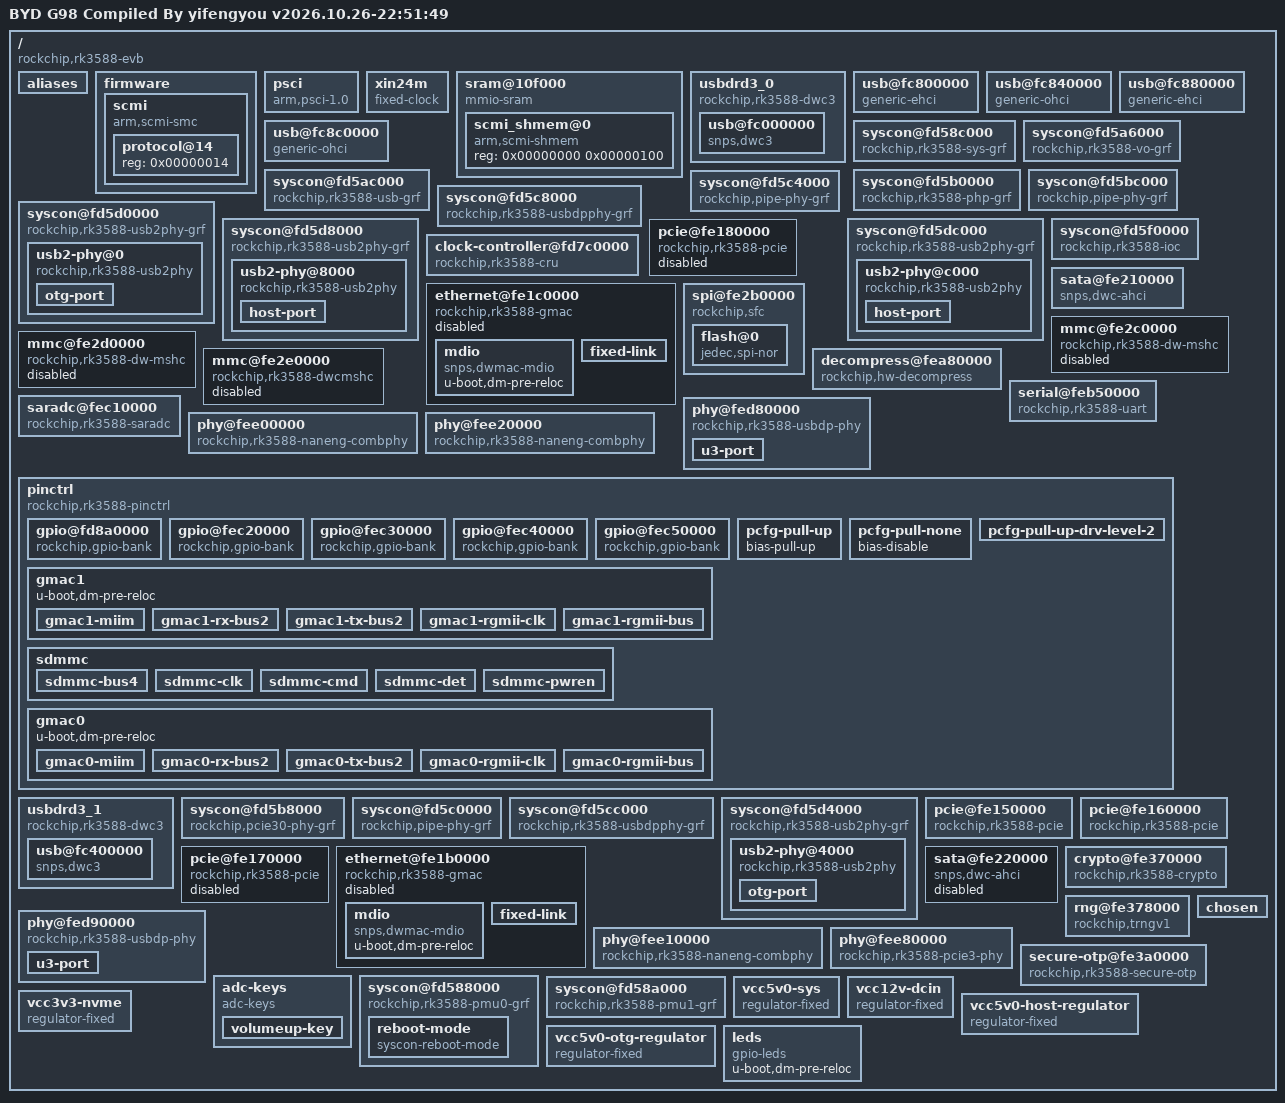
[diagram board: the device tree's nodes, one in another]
/dts-v1/;
// magic:		0xd00dfeed
// totalsize:		0x6047 (24647)
// off_dt_struct:	0x38
// off_dt_strings:	0x5850
// off_mem_rsvmap:	0x28
// version:		17
// last_comp_version:	16
// boot_cpuid_phys:	0x0
// size_dt_strings:	0x7f7
// size_dt_struct:	0x5818

/ {
    compatible = "rockchip,rk3588-evb", "rockchip,rk3588";
    #address-cells = <0x00000002>;
    #size-cells = <0x00000002>;
    model = "BYD G98 Compiled By yifengyou v2026.10.26-22:51:49";
    aliases {
        ethernet1 = "/pcie@fe170000";
        serial2 = "/serial@feb50000";
        spi0 = "/spi@fe2b0000";
        spi5 = "/spi@fe2b0000";
        gpio0 = "/pinctrl/gpio@fd8a0000";
        gpio1 = "/pinctrl/gpio@fec20000";
        gpio2 = "/pinctrl/gpio@fec30000";
        gpio3 = "/pinctrl/gpio@fec40000";
        gpio4 = "/pinctrl/gpio@fec50000";
        ethernet0 = "/pcie@fe180000";
        mmc0 = "/mmc@fe2e0000";
        mmc1 = "/mmc@fe2c0000";
    };
    firmware {
        u-boot,dm-spl;
        scmi {
            compatible = "arm,scmi-smc";
            shmem = <0x10000009>;
            arm,smc-id = <0x82000010>;
            #address-cells = <0x00000001>;
            #size-cells = <0x00000000>;
            u-boot,dm-spl;
            protocol@14 {
                reg = <0x00000014>;
                #clock-cells = <0x00000001>;
                u-boot,dm-spl;
                phandle = <0x1000000a>;
            };
        };
    };
    psci {
        compatible = "arm,psci-1.0";
        method = "smc";
        u-boot,dm-pre-reloc;
        status = "okay";
    };
    xin24m {
        compatible = "fixed-clock";
        #clock-cells = <0x00000000>;
        clock-frequency = <0x016e3600>;
        clock-output-names = "xin24m";
        u-boot,dm-pre-reloc;
        status = "okay";
    };
    sram@10f000 {
        compatible = "mmio-sram";
        reg = <0x00000000 0x0010f000 0x00000000 0x00000100>;
        #address-cells = <0x00000001>;
        #size-cells = <0x00000001>;
        ranges = <0x00000000 0x00000000 0x0010f000 0x00000100>;
        u-boot,dm-spl;
        scmi_shmem@0 {
            compatible = "arm,scmi-shmem";
            reg = <0x00000000 0x00000100>;
            u-boot,dm-spl;
            phandle = <0x10000009>;
        };
    };
    usbdrd3_0 {
        compatible = "rockchip,rk3588-dwc3", "rockchip,rk3399-dwc3";
        clocks = <0x1000000b 0x000001a3 0x1000000b 0x000001a2 0x1000000b 0x000001a1>;
        #address-cells = <0x00000002>;
        #size-cells = <0x00000002>;
        ranges;
        status = "okay";
        dr_mode = "otg";
        u-boot,dm-pre-reloc;
        usb@fc000000 {
            compatible = "snps,dwc3";
            reg = <0x00000000 0xfc000000 0x00000000 0x00400000>;
            interrupts = <0x00000000 0x000000dc 0x00000004>;
            power-domains = <0x1000000c 0x0000001f>;
            resets = <0x1000000b 0x000002a4>;
            reset-names = "usb3-otg";
            dr_mode = "otg";
            phys = <0x1000000d 0x1000000e>;
            phy-names = "usb2-phy", "usb3-phy";
            phy_type = "utmi_wide";
            snps,dis_enblslpm_quirk;
            snps,dis-u1-entry-quirk;
            snps,dis-u2-entry-quirk;
            snps,dis-u2-freeclk-exists-quirk;
            snps,dis-del-phy-power-chg-quirk;
            snps,dis-tx-ipgap-linecheck-quirk;
            status = "okay";
            maximum-speed = "super-speed";
            u-boot,dm-pre-reloc;
        };
    };
    usb@fc800000 {
        compatible = "generic-ehci";
        reg = <0x00000000 0xfc800000 0x00000000 0x00040000>;
        interrupts = <0x00000000 0x000000d7 0x00000004>;
        clocks = <0x1000000b 0x0000019d 0x1000000b 0x0000019e>;
        phys = <0x1000000f>;
        phy-names = "usb2-phy";
        power-domains = <0x1000000c 0x0000001f>;
        status = "okay";
        u-boot,dm-pre-reloc;
    };
    usb@fc840000 {
        compatible = "generic-ohci";
        reg = <0x00000000 0xfc840000 0x00000000 0x00040000>;
        interrupts = <0x00000000 0x000000d8 0x00000004>;
        clocks = <0x1000000b 0x0000019d 0x1000000b 0x0000019e>;
        phys = <0x1000000f>;
        phy-names = "usb2-phy";
        power-domains = <0x1000000c 0x0000001f>;
        status = "okay";
        u-boot,dm-pre-reloc;
    };
    usb@fc880000 {
        compatible = "generic-ehci";
        reg = <0x00000000 0xfc880000 0x00000000 0x00040000>;
        interrupts = <0x00000000 0x000000da 0x00000004>;
        clocks = <0x1000000b 0x0000019f 0x1000000b 0x000001a0>;
        phys = <0x10000010>;
        phy-names = "usb2-phy";
        power-domains = <0x1000000c 0x0000001f>;
        status = "okay";
        u-boot,dm-pre-reloc;
    };
    usb@fc8c0000 {
        compatible = "generic-ohci";
        reg = <0x00000000 0xfc8c0000 0x00000000 0x00040000>;
        interrupts = <0x00000000 0x000000db 0x00000004>;
        clocks = <0x1000000b 0x0000019f 0x1000000b 0x000001a0>;
        phys = <0x10000010>;
        phy-names = "usb2-phy";
        power-domains = <0x1000000c 0x0000001f>;
        status = "okay";
        u-boot,dm-pre-reloc;
    };
    syscon@fd58c000 {
        compatible = "rockchip,rk3588-sys-grf", "syscon";
        reg = <0x00000000 0xfd58c000 0x00000000 0x00001000>;
        u-boot,dm-spl;
        status = "okay";
        u-boot,dm-pre-reloc;
        phandle = <0x10000027>;
    };
    syscon@fd5a6000 {
        compatible = "rockchip,rk3588-vo-grf", "syscon";
        reg = <0x00000000 0xfd5a6000 0x00000000 0x00002000>;
        status = "okay";
        u-boot,dm-pre-reloc;
        phandle = <0x1000009b>;
    };
    syscon@fd5ac000 {
        compatible = "rockchip,rk3588-usb-grf", "syscon";
        reg = <0x00000000 0xfd5ac000 0x00000000 0x00004000>;
        u-boot,dm-pre-reloc;
        status = "okay";
        phandle = <0x10000099>;
    };
    syscon@fd5b0000 {
        compatible = "rockchip,rk3588-php-grf", "syscon";
        reg = <0x00000000 0xfd5b0000 0x00000000 0x00001000>;
        u-boot,dm-pre-reloc;
        status = "okay";
        phandle = <0x10000013>;
    };
    syscon@fd5bc000 {
        compatible = "rockchip,pipe-phy-grf", "syscon";
        reg = <0x00000000 0xfd5bc000 0x00000000 0x00000100>;
        u-boot,dm-pre-reloc;
        status = "okay";
        phandle = <0x1000009c>;
    };
    syscon@fd5c4000 {
        compatible = "rockchip,pipe-phy-grf", "syscon";
        reg = <0x00000000 0xfd5c4000 0x00000000 0x00000100>;
        u-boot,dm-pre-reloc;
        status = "okay";
        phandle = <0x1000009e>;
    };
    syscon@fd5c8000 {
        compatible = "rockchip,rk3588-usbdpphy-grf", "syscon";
        reg = <0x00000000 0xfd5c8000 0x00000000 0x00004000>;
        u-boot,dm-pre-reloc;
        status = "okay";
        phandle = <0x1000009a>;
    };
    syscon@fd5d0000 {
        compatible = "rockchip,rk3588-usb2phy-grf", "syscon", "simple-mfd";
        reg = <0x00000000 0xfd5d0000 0x00000000 0x00004000>;
        #address-cells = <0x00000001>;
        #size-cells = <0x00000001>;
        u-boot,dm-pre-reloc;
        status = "okay";
        phandle = <0x10000098>;
        usb2-phy@0 {
            compatible = "rockchip,rk3588-usb2phy";
            reg = <0x00000000 0x00000010>;
            interrupts = <0x00000000 0x00000189 0x00000004>;
            resets = <0x1000000b 0x000c0047 0x1000000b 0x00000488>;
            reset-names = "phy", "apb";
            clocks = <0x1000000b 0x000002b5>;
            #clock-cells = <0x00000000>;
            status = "okay";
            u-boot,dm-pre-reloc;
            otg-port {
                #phy-cells = <0x00000000>;
                status = "okay";
                u-boot,dm-pre-reloc;
                phy-supply = <0x10000011>;
                phandle = <0x1000000d>;
            };
        };
    };
    syscon@fd5d8000 {
        compatible = "rockchip,rk3588-usb2phy-grf", "syscon", "simple-mfd";
        reg = <0x00000000 0xfd5d8000 0x00000000 0x00004000>;
        #address-cells = <0x00000001>;
        #size-cells = <0x00000001>;
        status = "okay";
        u-boot,dm-pre-reloc;
        usb2-phy@8000 {
            compatible = "rockchip,rk3588-usb2phy";
            reg = <0x00008000 0x00000010>;
            interrupts = <0x00000000 0x00000187 0x00000004>;
            resets = <0x1000000b 0x000c0049 0x1000000b 0x0000048a>;
            reset-names = "phy", "apb";
            clocks = <0x1000000b 0x000002b5>;
            #clock-cells = <0x00000000>;
            status = "okay";
            u-boot,dm-pre-reloc;
            host-port {
                #phy-cells = <0x00000000>;
                status = "okay";
                phy-supply = <0x10000012>;
                u-boot,dm-pre-reloc;
                phandle = <0x1000000f>;
            };
        };
    };
    syscon@fd5dc000 {
        compatible = "rockchip,rk3588-usb2phy-grf", "syscon", "simple-mfd";
        reg = <0x00000000 0xfd5dc000 0x00000000 0x00004000>;
        #address-cells = <0x00000001>;
        #size-cells = <0x00000001>;
        status = "okay";
        u-boot,dm-pre-reloc;
        usb2-phy@c000 {
            compatible = "rockchip,rk3588-usb2phy";
            reg = <0x0000c000 0x00000010>;
            interrupts = <0x00000000 0x00000188 0x00000004>;
            resets = <0x1000000b 0x000c004a 0x1000000b 0x0000048b>;
            reset-names = "phy", "apb";
            clocks = <0x1000000b 0x000002b5>;
            #clock-cells = <0x00000000>;
            status = "okay";
            u-boot,dm-pre-reloc;
            host-port {
                #phy-cells = <0x00000000>;
                status = "okay";
                phy-supply = <0x10000012>;
                u-boot,dm-pre-reloc;
                phandle = <0x10000010>;
            };
        };
    };
    syscon@fd5f0000 {
        compatible = "rockchip,rk3588-ioc", "syscon";
        reg = <0x00000000 0xfd5f0000 0x00000000 0x00010000>;
        u-boot,dm-spl;
        phandle = <0x1000009f>;
    };
    clock-controller@fd7c0000 {
        compatible = "rockchip,rk3588-cru";
        rockchip,grf = <0x10000013>;
        reg = <0x00000000 0xfd7c0000 0x00000000 0x0005c000>;
        #clock-cells = <0x00000001>;
        #reset-cells = <0x00000001>;
        u-boot,dm-spl;
        status = "okay";
        phandle = <0x1000000b>;
    };
    pcie@fe180000 {
        compatible = "rockchip,rk3588-pcie", "snps,dw-pcie";
        #address-cells = <0x00000003>;
        #size-cells = <0x00000002>;
        bus-range = <0x00000030 0x0000003f>;
        clocks = <0x1000000b 0x00000151 0x1000000b 0x00000156 0x1000000b 0x0000014c 0x1000000b 0x0000015c 0x1000000b 0x00000161>;
        device_type = "pci";
        interrupts = <0x00000000 0x000000f8 0x00000004 0x00000000 0x000000f7 0x00000004 0x00000000 0x000000f6 0x00000004 0x00000000 0x000000f5 0x00000004 0x00000000 0x000000f4 0x00000004>;
        interrupt-names = "sys", "pmc", "msg", "legacy", "err";
        #interrupt-cells = <0x00000001>;
        interrupt-map-mask = <0x00000000 0x00000000 0x00000000 0x00000007>;
        interrupt-map = <0x00000000 0x00000000 0x00000000 0x00000001 0x1000001f 0x00000000 0x00000000 0x00000000 0x00000000 0x00000002 0x1000001f 0x00000001 0x00000000 0x00000000 0x00000000 0x00000003 0x1000001f 0x00000002 0x00000000 0x00000000 0x00000000 0x00000004 0x1000001f 0x00000003>;
        linux,pci-domain = <0x00000003>;
        num-ib-windows = <0x00000008>;
        num-ob-windows = <0x00000008>;
        max-link-speed = <0x00000002>;
        msi-map = <0x00003000 0x10000020 0x00003000 0x00001000>;
        num-lanes = <0x00000001>;
        phys = <0x10000021 0x00000002>;
        phy-names = "pcie-phy";
        power-domains = <0x1000000c 0x00000020>;
        ranges = <0x00000800 0x00000000 0xf3000000 0x00000000 0xf3000000 0x00000000 0x00100000 0x81000000 0x00000000 0xf3100000 0x00000000 0xf3100000 0x00000000 0x00100000 0x82000000 0x00000000 0xf3200000 0x00000000 0xf3200000 0x00000000 0x00e00000 0xc3000000 0x00000009 0xc0000000 0x00000009 0xc0000000 0x00000000 0x40000000>;
        reg = <0x0000000a 0x40c00000 0x00000000 0x00400000 0x00000000 0xfe180000 0x00000000 0x00010000>;
        reg-names = "pcie-dbi", "pcie-apb";
        resets = <0x1000000b 0x00000210>;
        reset-names = "pipe";
        status = "disabled";
        supports-clkreq;
        reset-gpios = <0x10000023 0x00000002 0x00000000>;
        vpcie3v3-supply = <0x10000024>;
        reset-delay-us = <0x000186a0>;
        u-boot,dm-pre-reloc;
    };
    ethernet@fe1c0000 {
        compatible = "rockchip,rk3588-gmac", "snps,dwmac-4.20a";
        reg = <0x00000000 0xfe1c0000 0x00000000 0x00010000>;
        interrupts = <0x00000000 0x000000ea 0x00000004 0x00000000 0x000000e9 0x00000004>;
        interrupt-names = "macirq", "eth_wake_irq";
        rockchip,grf = <0x10000027>;
        rockchip,php_grf = <0x10000013>;
        clocks = <0x1000000b 0x000002b4 0x1000000b 0x0000016d 0x1000000b 0x00000168 0x1000000b 0x00000143>;
        resets = <0x1000000b 0x0000020b>;
        reset-names = "stmmaceth";
        snps,mixed-burst;
        snps,tso;
        snps,axi-config = <0x10000028>;
        snps,mtl-rx-config = <0x10000029>;
        snps,mtl-tx-config = <0x1000002a>;
        status = "disabled";
        clock_in_out = "output";
        phy-mode = "rgmii-rxid";
        tx_delay = <0x00000042>;
        snps,reset-active-low;
        snps,reset-delays-us = <0x00000000 0x00004e20 0x000186a0>;
        snps,reset-gpio = <0x10000023 0x0000000b 0x00000001>;
        u-boot,dm-pre-reloc;
        phandle = <0x10000030>;
        mdio {
            compatible = "snps,dwmac-mdio";
            #address-cells = <0x00000001>;
            #size-cells = <0x00000000>;
            u-boot,dm-pre-reloc;
            status = "okay";
        };
        fixed-link {
            full-duplex;
            pause;
            speed = <0x000003e8>;
            u-boot,dm-pre-reloc;
            status = "okay";
        };
    };
    sata@fe210000 {
        compatible = "snps,dwc-ahci";
        reg = <0x00000000 0xfe210000 0x00000000 0x00001000>;
        clocks = <0x1000000b 0x00000171 0x1000000b 0x0000016e 0x1000000b 0x00000174 0x1000000b 0x00000163>;
        interrupts = <0x00000000 0x00000111 0x00000004>;
        interrupt-names = "hostc";
        phys = <0x10000026 0x00000001>;
        phy-names = "sata-phy";
        ports-implemented = <0x00000001>;
        power-domains = <0x1000000c 0x00000020>;
        status = "okay";
        u-boot,dm-pre-reloc;
    };
    spi@fe2b0000 {
        compatible = "rockchip,sfc";
        reg = <0x00000000 0xfe2b0000 0x00000000 0x00004000>;
        interrupts = <0x00000000 0x000000ce 0x00000004>;
        clocks = <0x1000000b 0x0000013d 0x1000000b 0x0000013e>;
        #address-cells = <0x00000001>;
        #size-cells = <0x00000000>;
        status = "okay";
        u-boot,dm-spl;
        u-boot,dm-pre-reloc;
        flash@0 {
            u-boot,dm-spl;
            compatible = "jedec,spi-nor";
            reg = <0x00000000>;
            spi-tx-bus-width = <0x00000001>;
            spi-rx-bus-width = <0x00000004>;
            spi-max-frequency = <0x05f5e100>;
            status = "okay";
            label = "sfc_nor";
            spi-4byte-addressing;
            broken-flash-reset;
            u-boot,dm-pre-reloc;
        };
    };
    mmc@fe2c0000 {
        compatible = "rockchip,rk3588-dw-mshc", "rockchip,rk3288-dw-mshc";
        reg = <0x00000000 0xfe2c0000 0x00000000 0x00004000>;
        interrupts = <0x00000000 0x000000cb 0x00000004>;
        clocks = <0x1000000a 0x00000009 0x1000000a 0x00000017 0x1000000b 0x000002c2 0x1000000b 0x000002c3>;
        fifo-depth = <0x00000100>;
        max-frequency = <0x0bebc200>;
        status = "disabled";
        bus-width = <0x00000004>;
        u-boot,dm-spl;
        cd-gpios = <0x10000035 0x00000004 0x00000000>;
        u-boot,dm-pre-reloc;
    };
    mmc@fe2d0000 {
        compatible = "rockchip,rk3588-dw-mshc", "rockchip,rk3288-dw-mshc";
        reg = <0x00000000 0xfe2d0000 0x00000000 0x00004000>;
        interrupts = <0x00000000 0x000000cc 0x00000004>;
        clocks = <0x1000000b 0x00000199 0x1000000b 0x0000019a 0x1000000b 0x000002c0 0x1000000b 0x000002c1>;
        fifo-depth = <0x00000100>;
        max-frequency = <0x0bebc200>;
        status = "disabled";
        u-boot,dm-pre-reloc;
    };
    mmc@fe2e0000 {
        compatible = "rockchip,rk3588-dwcmshc", "rockchip,dwcmshc-sdhci";
        reg = <0x00000000 0xfe2e0000 0x00000000 0x00010000>;
        interrupts = <0x00000000 0x000000cd 0x00000004>;
        clocks = <0x1000000b 0x0000013a 0x1000000b 0x00000138 0x1000000b 0x00000139 0x1000000b 0x0000013b 0x1000000b 0x0000013c>;
        max-frequency = <0x0bebc200>;
        status = "disabled";
        bus-width = <0x00000008>;
        u-boot,dm-spl;
        mmc-hs400-1_8v;
        mmc-hs400-enhanced-strobe;
        non-removable;
    };
    decompress@fea80000 {
        compatible = "rockchip,hw-decompress";
        reg = <0x00000000 0xfea80000 0x00000000 0x00001000>;
        interrupts = <0x00000000 0x00000055 0x00000004>;
        clocks = <0x1000000b 0x00000075 0x1000000b 0x00000077 0x1000000b 0x00000076>;
        resets = <0x1000000b 0x00000118>;
        reset-names = "dresetn";
        status = "okay";
        u-boot,dm-spl;
    };
    serial@feb50000 {
        compatible = "rockchip,rk3588-uart", "snps,dw-apb-uart";
        reg = <0x00000000 0xfeb50000 0x00000000 0x00000100>;
        interrupts = <0x00000000 0x0000014d 0x00000004>;
        clocks = <0x1000000b 0x000000bb 0x1000000b 0x000000ac>;
        reg-shift = <0x00000002>;
        reg-io-width = <0x00000004>;
        dmas = <0x10000015 0x0000000a 0x10000015 0x0000000b>;
        status = "okay";
        u-boot,dm-spl;
    };
    saradc@fec10000 {
        compatible = "rockchip,rk3588-saradc";
        reg = <0x00000000 0xfec10000 0x00000000 0x00010000>;
        interrupts = <0x00000000 0x0000018e 0x00000004>;
        #io-channel-cells = <0x00000001>;
        clocks = <0x1000000b 0x0000009d 0x1000000b 0x0000009c>;
        resets = <0x1000000b 0x000000be>;
        reset-names = "saradc-apb";
        status = "okay";
        u-boot,dm-pre-reloc;
        phandle = <0x100000c2>;
    };
    phy@fed80000 {
        compatible = "rockchip,rk3588-usbdp-phy";
        reg = <0x00000000 0xfed80000 0x00000000 0x00010000>;
        rockchip,u2phy-grf = <0x10000098>;
        rockchip,usb-grf = <0x10000099>;
        rockchip,usbdpphy-grf = <0x1000009a>;
        rockchip,vo-grf = <0x1000009b>;
        clocks = <0x1000000b 0x000002b6 0x1000000b 0x0000027f 0x1000000b 0x00000269>;
        resets = <0x1000000b 0x00000028 0x1000000b 0x00000029 0x1000000b 0x0000002a 0x1000000b 0x0000002b 0x1000000b 0x00000482>;
        reset-names = "init", "cmn", "lane", "pcs_apb", "pma_apb";
        status = "okay";
        u-boot,dm-pre-reloc;
        u3-port {
            #phy-cells = <0x00000000>;
            status = "okay";
            u-boot,dm-pre-reloc;
            maximum-speed = "high-speed";
            phandle = <0x1000000e>;
        };
    };
    phy@fee00000 {
        compatible = "rockchip,rk3588-naneng-combphy";
        reg = <0x00000000 0xfee00000 0x00000000 0x00000100>;
        #phy-cells = <0x00000001>;
        clocks = <0x1000000b 0x000002bd 0x1000000b 0x00000185>;
        resets = <0x1000000b 0x00020005 0x1000000b 0x000004d6>;
        reset-names = "combphy-apb", "combphy";
        rockchip,pipe-grf = <0x10000013>;
        rockchip,pipe-phy-grf = <0x1000009c>;
        status = "okay";
        phy-type = <0x00000001>;
        u-boot,dm-pre-reloc;
        phandle = <0x10000026>;
    };
    phy@fee20000 {
        compatible = "rockchip,rk3588-naneng-combphy";
        reg = <0x00000000 0xfee20000 0x00000000 0x00000100>;
        #phy-cells = <0x00000001>;
        clocks = <0x1000000b 0x000002bf 0x1000000b 0x00000187>;
        resets = <0x1000000b 0x00020007 0x1000000b 0x000004d8>;
        reset-names = "combphy-apb", "combphy";
        rockchip,pipe-grf = <0x10000013>;
        rockchip,pipe-phy-grf = <0x1000009e>;
        rockchip,pcie1ln-sel-bits = <0x00000100 0x00000001 0x00000001 0x00000000>;
        status = "okay";
        u-boot,dm-pre-reloc;
        phandle = <0x10000021>;
    };
    pinctrl {
        compatible = "rockchip,rk3588-pinctrl";
        rockchip,grf = <0x1000009f>;
        #address-cells = <0x00000002>;
        #size-cells = <0x00000002>;
        ranges;
        u-boot,dm-spl;
        u-boot,dm-pre-reloc;
        phandle = <0x100000a0>;
        gpio@fd8a0000 {
            compatible = "rockchip,gpio-bank";
            reg = <0x00000000 0xfd8a0000 0x00000000 0x00000100>;
            interrupts = <0x00000000 0x00000115 0x00000004>;
            clocks = <0x1000000b 0x00000284 0x1000000b 0x00000285>;
            gpio-controller;
            #gpio-cells = <0x00000002>;
            gpio-ranges = <0x100000a0 0x00000000 0x00000000 0x00000020>;
            interrupt-controller;
            #interrupt-cells = <0x00000002>;
            u-boot,dm-spl;
            status = "okay";
            u-boot,dm-pre-reloc;
            phandle = <0x10000035>;
        };
        gpio@fec20000 {
            compatible = "rockchip,gpio-bank";
            reg = <0x00000000 0xfec20000 0x00000000 0x00000100>;
            interrupts = <0x00000000 0x00000116 0x00000004>;
            clocks = <0x1000000b 0x0000007d 0x1000000b 0x0000007e>;
            gpio-controller;
            #gpio-cells = <0x00000002>;
            gpio-ranges = <0x100000a0 0x00000000 0x00000020 0x00000020>;
            interrupt-controller;
            #interrupt-cells = <0x00000002>;
            u-boot,dm-pre-reloc;
            status = "okay";
            phandle = <0x100000b3>;
        };
        gpio@fec30000 {
            compatible = "rockchip,gpio-bank";
            reg = <0x00000000 0xfec30000 0x00000000 0x00000100>;
            interrupts = <0x00000000 0x00000117 0x00000004>;
            clocks = <0x1000000b 0x0000007f 0x1000000b 0x00000080>;
            gpio-controller;
            #gpio-cells = <0x00000002>;
            gpio-ranges = <0x100000a0 0x00000000 0x00000040 0x00000020>;
            interrupt-controller;
            #interrupt-cells = <0x00000002>;
            u-boot,dm-pre-reloc;
            status = "okay";
        };
        gpio@fec40000 {
            compatible = "rockchip,gpio-bank";
            reg = <0x00000000 0xfec40000 0x00000000 0x00000100>;
            interrupts = <0x00000000 0x00000118 0x00000004>;
            clocks = <0x1000000b 0x00000081 0x1000000b 0x00000082>;
            gpio-controller;
            #gpio-cells = <0x00000002>;
            gpio-ranges = <0x100000a0 0x00000000 0x00000060 0x00000020>;
            interrupt-controller;
            #interrupt-cells = <0x00000002>;
            u-boot,dm-pre-reloc;
            status = "okay";
            phandle = <0x100000af>;
        };
        gpio@fec50000 {
            compatible = "rockchip,gpio-bank";
            reg = <0x00000000 0xfec50000 0x00000000 0x00000100>;
            interrupts = <0x00000000 0x00000119 0x00000004>;
            clocks = <0x1000000b 0x00000083 0x1000000b 0x00000084>;
            gpio-controller;
            #gpio-cells = <0x00000002>;
            gpio-ranges = <0x100000a0 0x00000000 0x00000080 0x00000020>;
            interrupt-controller;
            #interrupt-cells = <0x00000002>;
            u-boot,dm-pre-reloc;
            status = "okay";
            phandle = <0x10000023>;
        };
        pcfg-pull-up {
            bias-pull-up;
            u-boot,dm-spl;
            phandle = <0x100000a3>;
        };
        pcfg-pull-none {
            bias-disable;
            u-boot,dm-spl;
            phandle = <0x100000a1>;
        };
        pcfg-pull-up-drv-level-2 {
            bias-pull-up;
            drive-strength = <0x00000002>;
            u-boot,dm-spl;
            phandle = <0x100000a2>;
        };
        gmac1 {
            u-boot,dm-pre-reloc;
            gmac1-miim {
                rockchip,pins = <0x00000003 0x00000012 0x00000001 0x100000a1 0x00000003 0x00000013 0x00000001 0x100000a1>;
                u-boot,dm-pre-reloc;
                phandle = <0x1000002b>;
            };
            gmac1-rx-bus2 {
                rockchip,pins = <0x00000003 0x00000007 0x00000001 0x100000a1 0x00000003 0x00000008 0x00000001 0x100000a1 0x00000003 0x00000009 0x00000001 0x100000a1>;
                u-boot,dm-pre-reloc;
                phandle = <0x1000002d>;
            };
            gmac1-tx-bus2 {
                rockchip,pins = <0x00000003 0x0000000b 0x00000001 0x100000a1 0x00000003 0x0000000c 0x00000001 0x100000a1 0x00000003 0x0000000d 0x00000001 0x100000a1>;
                u-boot,dm-pre-reloc;
                phandle = <0x1000002c>;
            };
            gmac1-rgmii-clk {
                rockchip,pins = <0x00000003 0x00000005 0x00000001 0x100000a1 0x00000003 0x00000004 0x00000001 0x100000a1>;
                u-boot,dm-pre-reloc;
                phandle = <0x1000002e>;
            };
            gmac1-rgmii-bus {
                rockchip,pins = <0x00000003 0x00000002 0x00000001 0x100000a1 0x00000003 0x00000003 0x00000001 0x100000a1 0x00000003 0x00000000 0x00000001 0x100000a1 0x00000003 0x00000001 0x00000001 0x100000a1>;
                u-boot,dm-pre-reloc;
                phandle = <0x1000002f>;
            };
        };
        sdmmc {
            u-boot,dm-spl;
            sdmmc-bus4 {
                rockchip,pins = <0x00000004 0x00000018 0x00000001 0x100000a2 0x00000004 0x00000019 0x00000001 0x100000a2 0x00000004 0x0000001a 0x00000001 0x100000a2 0x00000004 0x0000001b 0x00000001 0x100000a2>;
                u-boot,dm-spl;
                phandle = <0x10000034>;
            };
            sdmmc-clk {
                rockchip,pins = <0x00000004 0x0000001d 0x00000001 0x100000a2>;
                u-boot,dm-spl;
                phandle = <0x10000031>;
            };
            sdmmc-cmd {
                rockchip,pins = <0x00000004 0x0000001c 0x00000001 0x100000a2>;
                u-boot,dm-spl;
                phandle = <0x10000032>;
            };
            sdmmc-det {
                rockchip,pins = <0x00000000 0x00000004 0x00000001 0x100000a3>;
                u-boot,dm-spl;
                phandle = <0x10000033>;
            };
            sdmmc-pwren {
                rockchip,pins = <0x00000000 0x00000005 0x00000002 0x100000a1>;
                u-boot,dm-spl;
            };
        };
        gmac0 {
            u-boot,dm-pre-reloc;
            gmac0-miim {
                rockchip,pins = <0x00000004 0x00000014 0x00000001 0x100000a1 0x00000004 0x00000015 0x00000001 0x100000a1>;
                u-boot,dm-pre-reloc;
                phandle = <0x100000b7>;
            };
            gmac0-rx-bus2 {
                rockchip,pins = <0x00000002 0x00000011 0x00000001 0x100000a1 0x00000002 0x00000012 0x00000001 0x100000a1 0x00000004 0x00000012 0x00000001 0x100000a1>;
                u-boot,dm-pre-reloc;
                phandle = <0x100000b9>;
            };
            gmac0-tx-bus2 {
                rockchip,pins = <0x00000002 0x0000000e 0x00000001 0x100000a1 0x00000002 0x0000000f 0x00000001 0x100000a1 0x00000002 0x00000010 0x00000001 0x100000a1>;
                u-boot,dm-pre-reloc;
                phandle = <0x100000b8>;
            };
            gmac0-rgmii-clk {
                rockchip,pins = <0x00000002 0x00000008 0x00000001 0x100000a1 0x00000002 0x0000000b 0x00000001 0x100000a1>;
                u-boot,dm-pre-reloc;
                phandle = <0x100000ba>;
            };
            gmac0-rgmii-bus {
                rockchip,pins = <0x00000002 0x00000006 0x00000001 0x100000a1 0x00000002 0x00000007 0x00000001 0x100000a1 0x00000002 0x00000009 0x00000001 0x100000a1 0x00000002 0x0000000a 0x00000001 0x100000a1>;
                u-boot,dm-pre-reloc;
                phandle = <0x100000bb>;
            };
        };
    };
    usbdrd3_1 {
        compatible = "rockchip,rk3588-dwc3", "rockchip,rk3399-dwc3";
        clocks = <0x1000000b 0x000001a6 0x1000000b 0x000001a5 0x1000000b 0x000001a4>;
        #address-cells = <0x00000002>;
        #size-cells = <0x00000002>;
        ranges;
        status = "okay";
        dr_mode = "host";
        u-boot,dm-pre-reloc;
        usb@fc400000 {
            compatible = "snps,dwc3";
            reg = <0x00000000 0xfc400000 0x00000000 0x00400000>;
            interrupts = <0x00000000 0x000000dd 0x00000004>;
            power-domains = <0x1000000c 0x0000001f>;
            resets = <0x1000000b 0x000002a7>;
            reset-names = "usb3-otg";
            dr_mode = "host";
            phys = <0x100000a7 0x100000a8>;
            phy-names = "usb2-phy", "usb3-phy";
            phy_type = "utmi_wide";
            snps,dis_enblslpm_quirk;
            snps,dis-u2-freeclk-exists-quirk;
            snps,dis-del-phy-power-chg-quirk;
            snps,dis-tx-ipgap-linecheck-quirk;
            status = "okay";
            maximum-speed = "super-speed";
            u-boot,dm-pre-reloc;
        };
    };
    syscon@fd5b8000 {
        compatible = "rockchip,pcie30-phy-grf", "syscon";
        reg = <0x00000000 0xfd5b8000 0x00000000 0x00010000>;
        u-boot,dm-pre-reloc;
        status = "okay";
        phandle = <0x100000c1>;
    };
    syscon@fd5c0000 {
        compatible = "rockchip,pipe-phy-grf", "syscon";
        reg = <0x00000000 0xfd5c0000 0x00000000 0x00000100>;
        u-boot,dm-pre-reloc;
        status = "okay";
        phandle = <0x100000c0>;
    };
    syscon@fd5cc000 {
        compatible = "rockchip,rk3588-usbdpphy-grf", "syscon";
        reg = <0x00000000 0xfd5cc000 0x00000000 0x00004000>;
        status = "okay";
        u-boot,dm-pre-reloc;
        phandle = <0x100000bf>;
    };
    syscon@fd5d4000 {
        compatible = "rockchip,rk3588-usb2phy-grf", "syscon", "simple-mfd";
        reg = <0x00000000 0xfd5d4000 0x00000000 0x00004000>;
        #address-cells = <0x00000001>;
        #size-cells = <0x00000001>;
        status = "okay";
        u-boot,dm-pre-reloc;
        phandle = <0x100000be>;
        usb2-phy@4000 {
            compatible = "rockchip,rk3588-usb2phy";
            reg = <0x00004000 0x00000010>;
            interrupts = <0x00000000 0x0000018a 0x00000004>;
            resets = <0x1000000b 0x000c0048 0x1000000b 0x00000489>;
            reset-names = "phy", "apb";
            clocks = <0x1000000b 0x000002b5>;
            #clock-cells = <0x00000000>;
            status = "okay";
            u-boot,dm-pre-reloc;
            otg-port {
                #phy-cells = <0x00000000>;
                status = "okay";
                phy-supply = <0x10000012>;
                u-boot,dm-pre-reloc;
                phandle = <0x100000a7>;
            };
        };
    };
    pcie@fe150000 {
        compatible = "rockchip,rk3588-pcie", "snps,dw-pcie";
        #address-cells = <0x00000003>;
        #size-cells = <0x00000002>;
        bus-range = <0x00000000 0x0000000f>;
        clocks = <0x1000000b 0x0000014e 0x1000000b 0x00000153 0x1000000b 0x00000149 0x1000000b 0x00000158 0x1000000b 0x0000015e>;
        device_type = "pci";
        interrupts = <0x00000000 0x00000107 0x00000004 0x00000000 0x00000106 0x00000004 0x00000000 0x00000105 0x00000004 0x00000000 0x00000104 0x00000004 0x00000000 0x00000103 0x00000004>;
        interrupt-names = "sys", "pmc", "msg", "legacy", "err";
        #interrupt-cells = <0x00000001>;
        interrupt-map-mask = <0x00000000 0x00000000 0x00000000 0x00000007>;
        interrupt-map = <0x00000000 0x00000000 0x00000000 0x00000001 0x100000aa 0x00000000 0x00000000 0x00000000 0x00000000 0x00000002 0x100000aa 0x00000001 0x00000000 0x00000000 0x00000000 0x00000003 0x100000aa 0x00000002 0x00000000 0x00000000 0x00000000 0x00000004 0x100000aa 0x00000003>;
        linux,pci-domain = <0x00000000>;
        num-ib-windows = <0x00000010>;
        num-ob-windows = <0x00000010>;
        max-link-speed = <0x00000003>;
        msi-map = <0x00000000 0x10000020 0x00000000 0x00001000>;
        num-lanes = <0x00000002>;
        phys = <0x100000ab>;
        phy-names = "pcie-phy";
        power-domains = <0x1000000c 0x00000022>;
        ranges = <0x00000800 0x00000000 0xf0000000 0x00000000 0xf0000000 0x00000000 0x00100000 0x81000000 0x00000000 0xf0100000 0x00000000 0xf0100000 0x00000000 0x00100000 0x82000000 0x00000000 0xf0200000 0x00000000 0xf0200000 0x00000000 0x00e00000 0xc3000000 0x00000009 0x00000000 0x00000009 0x00000000 0x00000000 0x40000000>;
        reg = <0x0000000a 0x40000000 0x00000000 0x00400000 0x00000000 0xfe150000 0x00000000 0x00010000>;
        reg-names = "pcie-dbi", "pcie-apb";
        resets = <0x1000000b 0x0000020d>;
        reset-names = "pipe";
        status = "okay";
        reset-gpios = <0x10000023 0x0000000e 0x00000000>;
        vpcie3v3-supply = <0x10000024>;
        rockchip,bifurcation;
        rockchip,phy-init-delay-us = <0x0000c350>;
        reset-delay-us = <0x000186a0>;
        u-boot,dm-pre-reloc;
    };
    pcie@fe160000 {
        compatible = "rockchip,rk3588-pcie", "snps,dw-pcie";
        #address-cells = <0x00000003>;
        #size-cells = <0x00000002>;
        bus-range = <0x00000010 0x0000001f>;
        clocks = <0x1000000b 0x0000014f 0x1000000b 0x00000154 0x1000000b 0x0000014a 0x1000000b 0x00000159 0x1000000b 0x0000015f>;
        device_type = "pci";
        interrupts = <0x00000000 0x00000102 0x00000004 0x00000000 0x00000101 0x00000004 0x00000000 0x00000100 0x00000004 0x00000000 0x000000ff 0x00000004 0x00000000 0x000000fe 0x00000004>;
        interrupt-names = "sys", "pmc", "msg", "legacy", "err";
        #interrupt-cells = <0x00000001>;
        interrupt-map-mask = <0x00000000 0x00000000 0x00000000 0x00000007>;
        interrupt-map = <0x00000000 0x00000000 0x00000000 0x00000001 0x100000ad 0x00000000 0x00000000 0x00000000 0x00000000 0x00000002 0x100000ad 0x00000001 0x00000000 0x00000000 0x00000000 0x00000003 0x100000ad 0x00000002 0x00000000 0x00000000 0x00000000 0x00000004 0x100000ad 0x00000003>;
        linux,pci-domain = <0x00000001>;
        num-ib-windows = <0x00000010>;
        num-ob-windows = <0x00000010>;
        max-link-speed = <0x00000003>;
        msi-map = <0x00001000 0x10000020 0x00001000 0x00001000>;
        num-lanes = <0x00000002>;
        phys = <0x100000ab>;
        phy-names = "pcie-phy";
        power-domains = <0x1000000c 0x00000020>;
        ranges = <0x00000800 0x00000000 0xf1000000 0x00000000 0xf1000000 0x00000000 0x00100000 0x81000000 0x00000000 0xf1100000 0x00000000 0xf1100000 0x00000000 0x00100000 0x82000000 0x00000000 0xf1200000 0x00000000 0xf1200000 0x00000000 0x00e00000 0xc3000000 0x00000009 0x40000000 0x00000009 0x40000000 0x00000000 0x40000000>;
        reg = <0x0000000a 0x40400000 0x00000000 0x00400000 0x00000000 0xfe160000 0x00000000 0x00010000>;
        reg-names = "pcie-dbi", "pcie-apb";
        resets = <0x1000000b 0x0000020e>;
        reset-names = "pipe";
        status = "okay";
        reset-gpios = <0x100000af 0x0000001c 0x00000000>;
        vpcie3v3-supply = <0x10000024>;
        rockchip,bifurcation;
        reset-delay-us = <0x000186a0>;
        rockchip,phy-init-delay-us = <0x0000c350>;
        u-boot,dm-pre-reloc;
    };
    pcie@fe170000 {
        compatible = "rockchip,rk3588-pcie", "snps,dw-pcie";
        #address-cells = <0x00000003>;
        #size-cells = <0x00000002>;
        bus-range = <0x00000020 0x0000002f>;
        clocks = <0x1000000b 0x00000150 0x1000000b 0x00000155 0x1000000b 0x0000014b 0x1000000b 0x0000015b 0x1000000b 0x00000160>;
        device_type = "pci";
        interrupts = <0x00000000 0x000000f3 0x00000004 0x00000000 0x000000f2 0x00000004 0x00000000 0x000000f1 0x00000004 0x00000000 0x000000f0 0x00000004 0x00000000 0x000000ef 0x00000004>;
        interrupt-names = "sys", "pmc", "msg", "legacy", "err";
        #interrupt-cells = <0x00000001>;
        interrupt-map-mask = <0x00000000 0x00000000 0x00000000 0x00000007>;
        interrupt-map = <0x00000000 0x00000000 0x00000000 0x00000001 0x100000b0 0x00000000 0x00000000 0x00000000 0x00000000 0x00000002 0x100000b0 0x00000001 0x00000000 0x00000000 0x00000000 0x00000003 0x100000b0 0x00000002 0x00000000 0x00000000 0x00000000 0x00000004 0x100000b0 0x00000003>;
        linux,pci-domain = <0x00000002>;
        num-ib-windows = <0x00000008>;
        num-ob-windows = <0x00000008>;
        max-link-speed = <0x00000002>;
        msi-map = <0x00002000 0x10000020 0x00002000 0x00001000>;
        num-lanes = <0x00000001>;
        phys = <0x100000b1 0x00000002>;
        phy-names = "pcie-phy";
        power-domains = <0x1000000c 0x00000020>;
        ranges = <0x00000800 0x00000000 0xf2000000 0x00000000 0xf2000000 0x00000000 0x00100000 0x81000000 0x00000000 0xf2100000 0x00000000 0xf2100000 0x00000000 0x00100000 0x82000000 0x00000000 0xf2200000 0x00000000 0xf2200000 0x00000000 0x00e00000 0xc3000000 0x00000009 0x80000000 0x00000009 0x80000000 0x00000000 0x40000000>;
        reg = <0x0000000a 0x40800000 0x00000000 0x00400000 0x00000000 0xfe170000 0x00000000 0x00010000>;
        reg-names = "pcie-dbi", "pcie-apb";
        resets = <0x1000000b 0x0000020f>;
        reset-names = "pipe";
        status = "disabled";
        supports-clkreq;
        reset-gpios = <0x100000b3 0x0000000c 0x00000000>;
        vpcie3v3-supply = <0x10000024>;
        reset-delay-us = <0x000186a0>;
        u-boot,dm-pre-reloc;
    };
    ethernet@fe1b0000 {
        compatible = "rockchip,rk3588-gmac", "snps,dwmac-4.20a";
        reg = <0x00000000 0xfe1b0000 0x00000000 0x00010000>;
        interrupts = <0x00000000 0x000000e3 0x00000004 0x00000000 0x000000e2 0x00000004>;
        interrupt-names = "macirq", "eth_wake_irq";
        rockchip,grf = <0x10000027>;
        rockchip,php_grf = <0x10000013>;
        clocks = <0x1000000b 0x000002b3 0x1000000b 0x0000016c 0x1000000b 0x00000167 0x1000000b 0x00000142>;
        resets = <0x1000000b 0x0000020a>;
        reset-names = "stmmaceth";
        snps,mixed-burst;
        snps,tso;
        snps,axi-config = <0x100000b4>;
        snps,mtl-rx-config = <0x100000b5>;
        snps,mtl-tx-config = <0x100000b6>;
        status = "disabled";
        clock_in_out = "output";
        phy-mode = "rgmii-rxid";
        tx_delay = <0x00000044>;
        snps,reset-active-low;
        snps,reset-delays-us = <0x00000000 0x00004e20 0x000186a0>;
        snps,reset-gpio = <0x100000af 0x00000018 0x00000001>;
        u-boot,dm-pre-reloc;
        phandle = <0x100000bc>;
        mdio {
            compatible = "snps,dwmac-mdio";
            #address-cells = <0x00000001>;
            #size-cells = <0x00000000>;
            u-boot,dm-pre-reloc;
            status = "okay";
        };
        fixed-link {
            full-duplex;
            pause;
            speed = <0x000003e8>;
            u-boot,dm-pre-reloc;
        };
    };
    sata@fe220000 {
        compatible = "snps,dwc-ahci";
        reg = <0x00000000 0xfe220000 0x00000000 0x00001000>;
        clocks = <0x1000000b 0x00000172 0x1000000b 0x0000016f 0x1000000b 0x00000175 0x1000000b 0x00000164>;
        interrupts = <0x00000000 0x00000112 0x00000004>;
        interrupt-names = "hostc";
        phys = <0x100000b1 0x00000001>;
        phy-names = "sata-phy";
        ports-implemented = <0x00000001>;
        power-domains = <0x1000000c 0x00000020>;
        status = "disabled";
        u-boot,dm-pre-reloc;
    };
    crypto@fe370000 {
        compatible = "rockchip,rk3588-crypto";
        reg = <0x00000000 0xfe370000 0x00000000 0x00004000>;
        clocks = <0x1000000a 0x00000014 0x1000000a 0x00000015>;
        clock-frequency = <0x14dc9380 0x14dc9380>;
        status = "okay";
        u-boot,dm-spl;
    };
    rng@fe378000 {
        compatible = "rockchip,trngv1";
        reg = <0x00000000 0xfe378000 0x00000000 0x00000200>;
        status = "okay";
        u-boot,dm-pre-reloc;
    };
    phy@fed90000 {
        compatible = "rockchip,rk3588-usbdp-phy";
        reg = <0x00000000 0xfed90000 0x00000000 0x00010000>;
        rockchip,u2phy-grf = <0x100000be>;
        rockchip,usb-grf = <0x10000099>;
        rockchip,usbdpphy-grf = <0x100000bf>;
        rockchip,vo-grf = <0x1000009b>;
        clocks = <0x1000000b 0x000002b6 0x1000000b 0x00000280 0x1000000b 0x0000026a>;
        resets = <0x1000000b 0x0000002f 0x1000000b 0x00000030 0x1000000b 0x00000031 0x1000000b 0x00000032 0x1000000b 0x00000484>;
        reset-names = "init", "cmn", "lane", "pcs_apb", "pma_apb";
        status = "okay";
        u-boot,dm-pre-reloc;
        u3-port {
            #phy-cells = <0x00000000>;
            status = "okay";
            maximum-speed = "high-speed";
            u-boot,dm-pre-reloc;
            phandle = <0x100000a8>;
        };
    };
    phy@fee10000 {
        compatible = "rockchip,rk3588-naneng-combphy";
        reg = <0x00000000 0xfee10000 0x00000000 0x00000100>;
        #phy-cells = <0x00000001>;
        clocks = <0x1000000b 0x000002be 0x1000000b 0x00000186>;
        resets = <0x1000000b 0x00020006 0x1000000b 0x000004d7>;
        reset-names = "combphy-apb", "combphy";
        rockchip,pipe-grf = <0x10000013>;
        rockchip,pipe-phy-grf = <0x100000c0>;
        rockchip,pcie1ln-sel-bits = <0x00000100 0x00000000 0x00000000 0x00000000>;
        status = "okay";
        u-boot,dm-pre-reloc;
        phandle = <0x100000b1>;
    };
    phy@fee80000 {
        compatible = "rockchip,rk3588-pcie3-phy";
        reg = <0x00000000 0xfee80000 0x00000000 0x00020000>;
        #phy-cells = <0x00000000>;
        clocks = <0x1000000b 0x00000188>;
        resets = <0x1000000b 0x0002000a>;
        reset-names = "phy";
        rockchip,pipe-grf = <0x10000013>;
        rockchip,phy-grf = <0x100000c1>;
        status = "okay";
        rockchip,pcie30-phymode = <0x00000000>;
        u-boot,dm-pre-reloc;
        phandle = <0x100000ab>;
    };
    chosen {
        stdout-path = "/serial@feb50000";
        u-boot,spl-boot-order = "/spi@fe2b0000/flash@0";
    };
    secure-otp@fe3a0000 {
        u-boot,dm-spl;
        compatible = "rockchip,rk3588-secure-otp";
        reg = <0x00000000 0xfe3a0000 0x00000000 0x00004000>;
    };
    adc-keys {
        compatible = "adc-keys";
        io-channels = <0x100000c2 0x00000001>;
        io-channel-names = "buttons";
        keyup-threshold-microvolt = <0x001b7740>;
        u-boot,dm-pre-reloc;
        status = "okay";
        volumeup-key {
            u-boot,dm-pre-reloc;
            linux,code = <0x00000073>;
            label = "volume up";
            press-threshold-microvolt = <0x000006d6>;
        };
    };
    syscon@fd588000 {
        compatible = "rockchip,rk3588-pmu0-grf", "syscon", "simple-mfd";
        reg = <0x00000000 0xfd588000 0x00000000 0x00002000>;
        status = "okay";
        u-boot,dm-pre-reloc;
        reboot-mode {
            status = "okay";
            compatible = "syscon-reboot-mode";
            offset = <0x00000080>;
            mode-bootloader = <0x5242c301>;
            mode-charge = <0x5242c30b>;
            mode-fastboot = <0x5242c309>;
            mode-loader = <0x5242c301>;
            mode-normal = <0x5242c300>;
            mode-maskrom = <0xef08a53c>;
            mode-recovery = <0x5242c303>;
            mode-ums = <0x5242c30c>;
            mode-panic = <0x5242c307>;
            mode-watchdog = <0x5242c308>;
            mode-quiescent = <0x5242c30e>;
            mode-winusb = <0x5242c30f>;
            u-boot,dm-pre-reloc;
        };
    };
    syscon@fd58a000 {
        status = "okay";
        u-boot,dm-pre-reloc;
        compatible = "rockchip,rk3588-pmu1-grf", "syscon";
        reg = <0x00000000 0xfd58a000 0x00000000 0x00002000>;
    };
    vcc5v0-sys {
        compatible = "regulator-fixed";
        regulator-always-on;
        regulator-boot-on;
        regulator-min-microvolt = <0x004c4b40>;
        regulator-max-microvolt = <0x004c4b40>;
        regulator-name = "vcc5v0_sys";
        vin-supply = <0x100000c3>;
        u-boot,dm-pre-reloc;
        phandle = <0x100000c6>;
    };
    vcc12v-dcin {
        compatible = "regulator-fixed";
        regulator-always-on;
        regulator-boot-on;
        regulator-min-microvolt = <0x00b71b00>;
        regulator-max-microvolt = <0x00b71b00>;
        regulator-name = "vcc12v_dcin";
        u-boot,dm-pre-reloc;
        phandle = <0x100000c3>;
    };
    vcc3v3-nvme {
        compatible = "regulator-fixed";
        regulator-min-microvolt = <0x00325aa0>;
        regulator-max-microvolt = <0x00325aa0>;
        regulator-name = "vcc3v3_nvme";
        vin-supply = <0x100000c3>;
        enable-active-high;
        gpios = <0x100000af 0x0000001d 0x00000000>;
        startup-delay-us = <0x00001d4c>;
        regulator-always-on;
        u-boot,dm-pre-reloc;
        phandle = <0x10000024>;
    };
    vcc5v0-host-regulator {
        compatible = "regulator-fixed";
        enable-active-high;
        gpio = <0x10000023 0x00000008 0x00000000>;
        regulator-name = "vcc5v0_host";
        regulator-boot-on;
        regulator-always-on;
        regulator-min-microvolt = <0x004c4b40>;
        regulator-max-microvolt = <0x004c4b40>;
        vin-supply = <0x100000c6>;
        u-boot,dm-pre-reloc;
        phandle = <0x10000012>;
    };
    vcc5v0-otg-regulator {
        compatible = "regulator-fixed";
        enable-active-high;
        gpio = <0x10000023 0x00000007 0x00000000>;
        regulator-min-microvolt = <0x004c4b40>;
        regulator-max-microvolt = <0x004c4b40>;
        regulator-name = "vcc5v0_otg";
        vin-supply = <0x100000c6>;
        u-boot,dm-pre-reloc;
        phandle = <0x10000011>;
    };
    leds {
        compatible = "gpio-leds";
        status = "okay";
        u-boot,dm-pre-reloc;
    };
};
